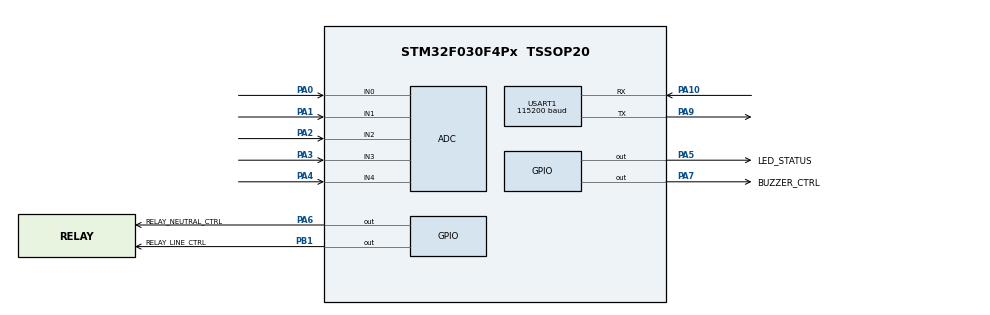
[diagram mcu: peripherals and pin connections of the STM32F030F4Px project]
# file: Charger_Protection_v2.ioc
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ADC.ContinuousConvMode=DISABLE
ADC.DMAContinuousRequests=ENABLE
ADC.EOCSelection=ADC_EOC_SEQ_CONV
ADC.ExternalTrigConv=ADC_EXTERNALTRIGCONV_T1_TRGO
ADC.SamplingTime=ADC_SAMPLETIME_41CYCLES_5
Dma.ADC.0.Direction=DMA_PERIPH_TO_MEMORY
Dma.ADC.0.Instance=DMA1_Channel1
Dma.ADC.0.MemDataAlignment=DMA_MDATAALIGN_HALFWORD
Dma.ADC.0.MemInc=DMA_MINC_ENABLE
Dma.ADC.0.Mode=DMA_CIRCULAR
Dma.ADC.0.PeriphDataAlignment=DMA_PDATAALIGN_HALFWORD
Dma.ADC.0.PeriphInc=DMA_PINC_DISABLE
Dma.ADC.0.Priority=DMA_PRIORITY_HIGH
Dma.Request0=ADC
Mcu.Family=STM32F0
Mcu.Name=STM32F030F4Px
Mcu.Package=TSSOP20
NVIC.DMA1_Channel1_IRQn=true\:1\:0\:false\:false\:true\:false\:true\:true
NVIC.USART1_IRQn=true\:0\:0\:false\:false\:true\:false\:true\:true
PA0.Mode=IN0
PA0.Signal=ADC_IN0
PA1.Mode=IN1
PA1.Signal=ADC_IN1
PA10.GPIO_PuPd=GPIO_PULLUP
PA10.Mode=Asynchronous
PA10.Signal=USART1_RX
PA13.Mode=Serial_Wire
PA13.Signal=SYS_SWDIO
PA14.Mode=Serial_Wire
PA14.Signal=SYS_SWCLK
PA2.Mode=IN2
PA2.Signal=ADC_IN2
PA3.Mode=IN3
PA3.Signal=ADC_IN3
PA4.Mode=IN4
PA4.Signal=ADC_IN4
PA5.GPIO_Label=LED_STATUS
PA5.GPIO_PuPd=GPIO_PULLDOWN
PA5.Signal=GPIO_Output
PA6.GPIO_Label=RELAY_NEUTRAL_CTRL
PA6.GPIO_PuPd=GPIO_PULLDOWN
PA6.Signal=GPIO_Output
PA7.GPIO_Label=BUZZER_CTRL
PA7.GPIO_PuPd=GPIO_PULLDOWN
PA7.Signal=GPIO_Output
PA9.GPIO_PuPd=GPIO_PULLUP
PA9.Mode=Asynchronous
PA9.Signal=USART1_TX
PB1.GPIO_Label=RELAY_LINE_CTRL
PB1.GPIO_PuPd=GPIO_PULLDOWN
PB1.Signal=GPIO_Output
PF0-OSC_IN.Mode=HSE-External-Oscillator
PF0-OSC_IN.Signal=RCC_OSC_IN
PF1-OSC_OUT.Mode=HSE-External-Oscillator
PF1-OSC_OUT.Signal=RCC_OSC_OUT
ProjectManager.HeapSize=0x150
ProjectManager.StackSize=0x300
ProjectManager.TargetToolchain=STM32CubeIDE
RCC.AHBFreq_Value=48000000
RCC.APB1Freq_Value=48000000
RCC.APB1TimFreq_Value=48000000
RCC.HCLKFreq_Value=48000000
RCC.PLLMUL=RCC_PLL_MUL12
RCC.SYSCLKFreq_VALUE=48000000
RCC.SYSCLKSource=RCC_SYSCLKSOURCE_PLLCLK
TIM1.Period=99
TIM1.Prescaler=47
TIM1.TIM_MasterOutputTrigger=TIM_TRGO_UPDATE
USART1.BaudRate=115200
USART1.VirtualMode=VM_ASYNC
VP_TIM1_VS_ClockSourceINT.Mode=Internal
VP_USART1_VS_Async.Mode=VM_ASYNC
board=custom

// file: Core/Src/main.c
/* USER CODE BEGIN Header */
/**
  ******************************************************************************
  * @file           : main.c
  * @brief          : Main program body
  ******************************************************************************
  * @attention
  *
  * Copyright (c) 2026 STMicroelectronics.
  * All rights reserved.
  *
  * This software is licensed under terms that can be found in the LICENSE file
  * in the root directory of this software component.
  * If no LICENSE file comes with this software, it is provided AS-IS.
  *
  ******************************************************************************
  */
/* USER CODE END Header */
#include "main.h"
#include "adc.h"
#include "dma.h"
#include "usart.h"
#include "tim.h"
#include "gpio.h"

/* USER CODE BEGIN Includes */
#include "Rte.h"
#include "Measurement.h"
#include "Protection.h"
#include "Scheduler.h"

#include "../Calib/Calib.h"
/* USER CODE END Includes */

void SystemClock_Config(void);

int main(void)
{

  /* MCU Configuration--------------------------------------------------------*/

  /* Reset of all peripherals, Initializes the Flash interface and the Systick. */
  LL_APB1_GRP2_EnableClock(LL_APB1_GRP2_PERIPH_SYSCFG);
  LL_APB1_GRP1_EnableClock(LL_APB1_GRP1_PERIPH_PWR);

  /* SysTick_IRQn interrupt configuration */
  NVIC_SetPriority(SysTick_IRQn, 3);

  /* Configure the system clock */
  SystemClock_Config();

  /* Initialize all configured peripherals */
  MX_GPIO_Init();
  MX_DMA_Init();
  MX_ADC_Init();
  MX_USART1_UART_Init();
  MX_TIM1_Init();
  /* USER CODE BEGIN 2 */
  Calib_Init();
  ProtectionInit();
  MeasurementInit();
  Com_Init();
  Scheduler_Init();
  /* USER CODE END 2 */

  /* Infinite loop */
  while (1)
  {

    /* USER CODE BEGIN 3 */
    Scheduler_MainFunction();
  }
  /* USER CODE END 3 */
}

void SystemClock_Config(void)
{
  LL_FLASH_SetLatency(LL_FLASH_LATENCY_1);
  while(LL_FLASH_GetLatency() != LL_FLASH_LATENCY_1)
  {
  }
  LL_RCC_HSI_Enable();

   /* Wait till HSI is ready */
  while(LL_RCC_HSI_IsReady() != 1)
  {

  }
  LL_RCC_HSI_SetCalibTrimming(16);
  LL_RCC_HSI14_Enable();

   /* Wait till HSI14 is ready */
  while(LL_RCC_HSI14_IsReady() != 1)
  {

  }
  LL_RCC_HSI14_SetCalibTrimming(16);
  LL_RCC_PLL_ConfigDomain_SYS(LL_RCC_PLLSOURCE_HSI_DIV_2, LL_RCC_PLL_MUL_12);
  LL_RCC_PLL_Enable();

   /* Wait till PLL is ready */
  while(LL_RCC_PLL_IsReady() != 1)
  {

  }
  LL_RCC_SetAHBPrescaler(LL_RCC_SYSCLK_DIV_1);
  LL_RCC_SetAPB1Prescaler(LL_RCC_APB1_DIV_1);
  LL_RCC_SetSysClkSource(LL_RCC_SYS_CLKSOURCE_PLL);

   /* Wait till System clock is ready */
  while(LL_RCC_GetSysClkSource() != LL_RCC_SYS_CLKSOURCE_STATUS_PLL)
  {

  }
  LL_Init1msTick(48000000);
  LL_SetSystemCoreClock(48000000);
  LL_RCC_HSI14_EnableADCControl();
  LL_RCC_SetUSARTClockSource(LL_RCC_USART1_CLKSOURCE_PCLK1);
}

void Error_Handler(void)
{
  /* USER CODE BEGIN Error_Handler_Debug */
  /* User can add his own implementation to report the HAL error return state */
  Rte_Call_Protection_EmergencyStop();
  __disable_irq();
  while (1)
  {
    /* The 1 ms SysTick counter keeps running with IRQs masked. Poll it so
     * the fault LED and buzzer continue cycling after a fatal DMA error. */
    if (LL_SYSTICK_IsActiveCounterFlag() != 0U)
    {
      Rte_Call_Protection_Tick1msISR();
    }
  }
  /* USER CODE END Error_Handler_Debug */
}
